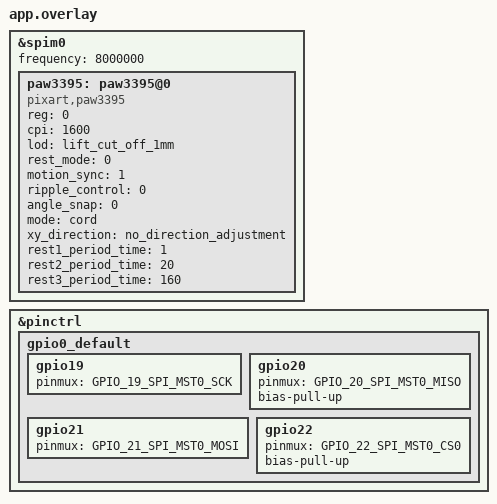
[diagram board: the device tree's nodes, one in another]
/* Copyright Statement:
 *
 * (C) 2024  Airoha Technology Corp. All rights reserved.
 *
 * This software/firmware and related documentation ("Airoha Software") are
 * protected under relevant copyright laws. The information contained herein
 * is confidential and proprietary to Airoha Technology Corp. ("Airoha") and/or its licensors.
 * Without the prior written permission of Airoha and/or its licensors,
 * any reproduction, modification, use or disclosure of Airoha Software,
 * and information contained herein, in whole or in part, shall be strictly prohibited.
 * You may only use, reproduce, modify, or distribute (as applicable) Airoha Software
 * if you have agreed to and been bound by the applicable license agreement with
 * Airoha ("License Agreement") and been granted explicit permission to do so within
 * the License Agreement ("Permitted User").  If you are not a Permitted User,
 * please cease any access or use of Airoha Software immediately.
 * BY OPENING THIS FILE, RECEIVER HEREBY UNEQUIVOCALLY ACKNOWLEDGES AND AGREES
 * THAT AIROHA SOFTWARE RECEIVED FROM AIROHA AND/OR ITS REPRESENTATIVES
 * ARE PROVIDED TO RECEIVER ON AN "AS-IS" BASIS ONLY. AIROHA EXPRESSLY DISCLAIMS ANY AND ALL
 * WARRANTIES, EXPRESS OR IMPLIED, INCLUDING BUT NOT LIMITED TO THE IMPLIED WARRANTIES OF
 * MERCHANTABILITY, FITNESS FOR A PARTICULAR PURPOSE OR NONINFRINGEMENT.
 * NEITHER DOES AIROHA PROVIDE ANY WARRANTY WHATSOEVER WITH RESPECT TO THE
 * SOFTWARE OF ANY THIRD PARTY WHICH MAY BE USED BY, INCORPORATED IN, OR
 * SUPPLIED WITH AIROHA SOFTWARE, AND RECEIVER AGREES TO LOOK ONLY TO SUCH
 * THIRD PARTY FOR ANY WARRANTY CLAIM RELATING THERETO. RECEIVER EXPRESSLY ACKNOWLEDGES
 * THAT IT IS RECEIVER'S SOLE RESPONSIBILITY TO OBTAIN FROM ANY THIRD PARTY ALL PROPER LICENSES
 * CONTAINED IN AIROHA SOFTWARE. AIROHA SHALL ALSO NOT BE RESPONSIBLE FOR ANY AIROHA
 * SOFTWARE RELEASES MADE TO RECEIVER'S SPECIFICATION OR TO CONFORM TO A PARTICULAR
 * STANDARD OR OPEN FORUM. RECEIVER'S SOLE AND EXCLUSIVE REMEDY AND AIROHA'S ENTIRE AND
 * CUMULATIVE LIABILITY WITH RESPECT TO AIROHA SOFTWARE RELEASED HEREUNDER WILL BE,
 * AT AIROHA'S OPTION, TO REVISE OR REPLACE AIROHA SOFTWARE AT ISSUE,
 * OR REFUND ANY SOFTWARE LICENSE FEES OR SERVICE CHARGE PAID BY RECEIVER TO
 * AIROHA FOR SUCH AIROHA SOFTWARE AT ISSUE.
 */


&spim0 {
    frequency = <8000000>;
    status = "okay";
	paw3395: paw3395@0{
		compatible = "pixart,paw3395";
		reg= <0>;
		cpi = <1600>;
		lod = "lift_cut_off_1mm";
		rest_mode = <0>;
		motion_sync = <1>;
		ripple_control = <0>;
		angle_snap = <0>;
		mode = "cord";
		xy_direction = "no_direction_adjustment";
		rest1_period_time = <1>;
		rest2_period_time = <20>;
		rest3_period_time = <160>;
		status = "okay";
    };
};

&pinctrl {
    gpio0_default: gpio0_default {
        /** SPI pins for motion sensor */
        gpio19{
            pinmux = <GPIO_19_SPI_MST0_SCK>;
        };
        gpio20{
            pinmux = <GPIO_20_SPI_MST0_MISO>;
            bias-pull-up;
        };
        gpio21{
            pinmux = <GPIO_21_SPI_MST0_MOSI>;
        };
        gpio22{
            pinmux = <GPIO_22_SPI_MST0_CS0>;
            bias-pull-up;
        };
    };
};
